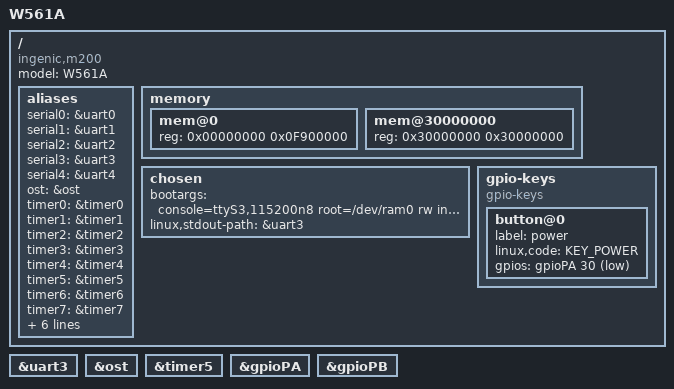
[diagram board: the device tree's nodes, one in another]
/*
 * w561a.dts - Device Tree file for W561A board
 * Copyright (C) Harvis Wang<jiankangshiye@aliyun.com>
 */

/dts-v1/;

#include "include/dt-bindings/gpio/gpio.h"
#include "include/dt-bindings/input/input.h"

#include "m200.dtsi"

/ {
    model = "W561A";
    compatible = "ingenic,m200";

    aliases {
        serial0 = &uart0;
        serial1 = &uart1;
        serial2 = &uart2;
        serial3 = &uart3;
        serial4 = &uart4;

        ost = &ost;

        timer0 = &timer0;
        timer1 = &timer1;
        timer2 = &timer2;
        timer3 = &timer3;
        timer4 = &timer4;
        timer5 = &timer5;
        timer6 = &timer6;
        timer7 = &timer7;

        gpio0 = &gpioPA; /* used in gpio_interrupt_of_init() */
        gpio1 = &gpioPB;
        gpio2 = &gpioPC;
        gpio3 = &gpioPD;
        gpio4 = &gpioPE;
        gpio5 = &gpioPF;
    };

    memory {
        #address-cells = <1>;
        #size-cells    = <1>;

        mem@0 {
            device_type = "memory";
            reg = <0x00000000 0x0F900000>;
        };

        mem@30000000 {
            device_type = "memory";
            reg = <0x30000000 0x30000000>;
        };
    };

    chosen {
        bootargs = "console=ttyS3,115200n8 root=/dev/ram0 rw init=/init rd_start=0x81ef8000 rd_size=0xb0081";
        linux,stdout-path = &uart3;
        //linux,initrd-start = <0x81EF8000>; /* rd_start=0x81ef8000 not works TODO */
        //linux,initrd-end   = <0x81EC9EF4>; /* rd_size=0xb1ef4 */
    };

    gpio-keys {
        compatible = "gpio-keys";
        #address-cells = <1>;
        #size-cells = <0>;

        button@0 {
            label = "power";
            linux,code = <KEY_POWER>;
            gpios = <&gpioPA 30 GPIO_ACTIVE_LOW>;
        };
    };
};

&uart3 {
    status = "okay";
};

&ost {
    status = "okay";
};

&timer5 {
    status = "okay";
};

&gpioPA {
    status = "okay";
};

&gpioPB {
    status = "okay";
};
